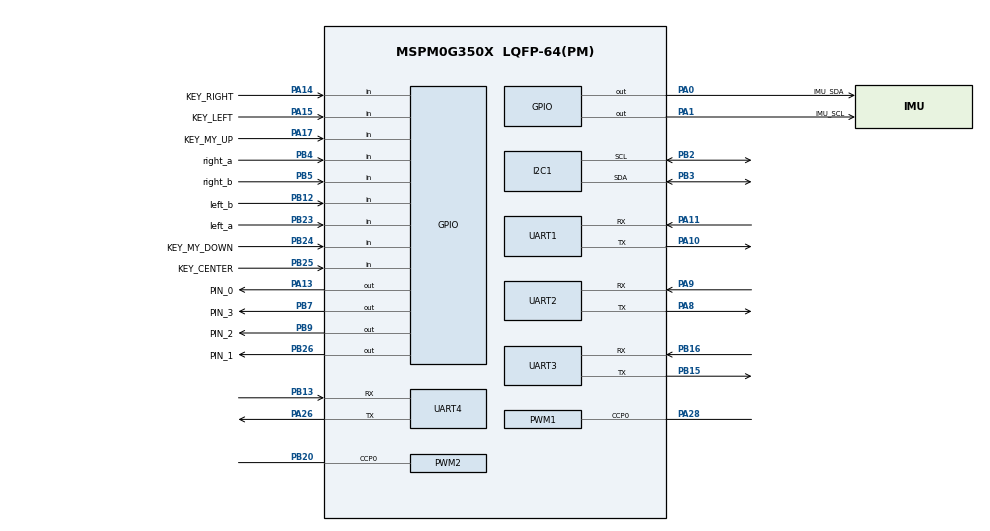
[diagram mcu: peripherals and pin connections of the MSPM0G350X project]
/**
 * @cliArgs --device "MSPM0G350X" --part "Default" --package "LQFP-64(PM)" --product "mspm0_sdk@2.09.00.00"
 * @versions {"tool":"1.27.0+4565"}
 */

/**
 * Import the modules used in this configuration.
 */
const GPIO    = scripting.addModule("/ti/driverlib/GPIO", {}, false);
const GPIO1   = GPIO.addInstance();
const GPIO2   = GPIO.addInstance();
const GPIO3   = GPIO.addInstance();
const GPIO4   = GPIO.addInstance();
const GPIO5   = GPIO.addInstance();
const GPIO7   = GPIO.addInstance();
const GPIO8   = GPIO.addInstance();
const I2C     = scripting.addModule("/ti/driverlib/I2C", {}, false);
const I2C1    = I2C.addInstance();
const PWM     = scripting.addModule("/ti/driverlib/PWM", {}, false);
const PWM1    = PWM.addInstance();
const PWM2    = PWM.addInstance();
const SYSCTL  = scripting.addModule("/ti/driverlib/SYSCTL");
const SYSTICK = scripting.addModule("/ti/driverlib/SYSTICK");
const UART    = scripting.addModule("/ti/driverlib/UART", {}, false);
const UART1   = UART.addInstance();
const UART2   = UART.addInstance();
const UART3   = UART.addInstance();
const UART4   = UART.addInstance();

/**
 * Write custom configuration values to the imported modules.
 */
const divider9       = system.clockTree["UDIV"];
divider9.divideValue = 2;

const gate7  = system.clockTree["MFCLKGATE"];
gate7.enable = true;

const gate8  = system.clockTree["MFPCLKGATE"];
gate8.enable = true;

const multiplier2         = system.clockTree["PLL_QDIV"];
multiplier2.multiplyValue = 4;

const mux4       = system.clockTree["EXHFMUX"];
mux4.inputSelect = "EXHFMUX_XTAL";

const mux8       = system.clockTree["HSCLKMUX"];
mux8.inputSelect = "HSCLKMUX_SYSPLL0";

const mux12       = system.clockTree["SYSPLLMUX"];
mux12.inputSelect = "zSYSPLLMUX_HFCLK";

const pinFunction3     = system.clockTree["HFCLKEXT"];
pinFunction3.inputFreq = 40;

const pinFunction4        = system.clockTree["HFXT"];
pinFunction4.inputFreq    = 40;
pinFunction4.enable       = true;
pinFunction4.HFXTStartup  = 100;
pinFunction4.HFCLKMonitor = true;

GPIO1.$name                         = "MOTOR_DIR_LEFT1";
GPIO1.associatedPins[0].$name       = "PIN_0";
GPIO1.associatedPins[0].pin.$assign = "PA13";

const Board = scripting.addModule("/ti/driverlib/Board", {}, false);

GPIO2.$name                         = "MOTOR_DIR_LEFT2";
GPIO2.associatedPins[0].$name       = "PIN_1";
GPIO2.associatedPins[0].pin.$assign = "PB26";

GPIO3.$name                         = "MOTOR_DIR_RIGHT1";
GPIO3.associatedPins[0].$name       = "PIN_2";
GPIO3.associatedPins[0].pin.$assign = "PB9";

GPIO4.$name                         = "MOTOR_DIR_RIGHT2";
GPIO4.associatedPins[0].$name       = "PIN_3";
GPIO4.associatedPins[0].pin.$assign = "PB7";

GPIO5.$name                              = "ENCODER";
GPIO5.associatedPins.create(4);
GPIO5.associatedPins[0].$name            = "left_a";
GPIO5.associatedPins[0].direction        = "INPUT";
GPIO5.associatedPins[0].internalResistor = "PULL_DOWN";
GPIO5.associatedPins[0].assignedPort     = "PORTB";
GPIO5.associatedPins[0].interruptEn      = true;
GPIO5.associatedPins[0].polarity         = "RISE";
GPIO5.associatedPins[0].pin.$assign      = "PB23";
GPIO5.associatedPins[1].$name            = "left_b";
GPIO5.associatedPins[1].direction        = "INPUT";
GPIO5.associatedPins[1].assignedPort     = "PORTB";
GPIO5.associatedPins[1].internalResistor = "PULL_UP";
GPIO5.associatedPins[1].interruptEn      = true;
GPIO5.associatedPins[1].polarity         = "FALL";
GPIO5.associatedPins[1].pin.$assign      = "PB12";
GPIO5.associatedPins[2].$name            = "right_a";
GPIO5.associatedPins[2].direction        = "INPUT";
GPIO5.associatedPins[2].assignedPort     = "PORTB";
GPIO5.associatedPins[2].interruptEn      = true;
GPIO5.associatedPins[2].internalResistor = "PULL_DOWN";
GPIO5.associatedPins[2].polarity         = "RISE";
GPIO5.associatedPins[2].pin.$assign      = "PB4";
GPIO5.associatedPins[3].$name            = "right_b";
GPIO5.associatedPins[3].direction        = "INPUT";
GPIO5.associatedPins[3].assignedPort     = "PORTB";
GPIO5.associatedPins[3].internalResistor = "PULL_UP";
GPIO5.associatedPins[3].interruptEn      = true;
GPIO5.associatedPins[3].polarity         = "FALL";
GPIO5.associatedPins[3].pin.$assign      = "PB5";

/* GRAY (PB10/PB11) 已移除：SERIAL_DAT/SERIAL_CLK 无代码引用，
 * 且其配套的 ADC12_0 外设已删除，属残留配置。 */

GPIO7.$name                          = "IMU";
GPIO7.associatedPins.create(2);
GPIO7.associatedPins[0].$name        = "IMU_SDA";
GPIO7.associatedPins[0].initialValue = "SET";
GPIO7.associatedPins[0].ioStructure  = "OD";
GPIO7.associatedPins[0].pin.$assign  = "PA0";
GPIO7.associatedPins[1].$name        = "IMU_SCL";
GPIO7.associatedPins[1].initialValue = "SET";
GPIO7.associatedPins[1].ioStructure  = "OD";
GPIO7.associatedPins[1].pin.$assign  = "PA1";

GPIO8.$name                              = "KEY";
GPIO8.associatedPins.create(5);
GPIO8.associatedPins[0].$name            = "KEY_MY_UP";
GPIO8.associatedPins[0].direction        = "INPUT";
GPIO8.associatedPins[0].internalResistor = "PULL_UP";
GPIO8.associatedPins[0].assignedPort     = "PORTA";
GPIO8.associatedPins[0].assignedPin      = "17";
GPIO8.associatedPins[0].pin.$assign      = "PA17";
GPIO8.associatedPins[1].$name            = "KEY_MY_DOWN";
GPIO8.associatedPins[1].direction        = "INPUT";
GPIO8.associatedPins[1].assignedPort     = "PORTB";
GPIO8.associatedPins[1].assignedPin      = "24";
GPIO8.associatedPins[1].internalResistor = "PULL_UP";
GPIO8.associatedPins[1].pin.$assign      = "PB24";
GPIO8.associatedPins[2].$name            = "KEY_LEFT";
GPIO8.associatedPins[2].direction        = "INPUT";
GPIO8.associatedPins[2].internalResistor = "PULL_UP";
GPIO8.associatedPins[2].assignedPort     = "PORTA";
GPIO8.associatedPins[2].assignedPin      = "15";
GPIO8.associatedPins[2].pin.$assign      = "PA15";
GPIO8.associatedPins[3].$name            = "KEY_RIGHT";
GPIO8.associatedPins[3].direction        = "INPUT";
GPIO8.associatedPins[3].assignedPort     = "PORTA";
GPIO8.associatedPins[3].assignedPin      = "14";
GPIO8.associatedPins[3].internalResistor = "PULL_UP";
GPIO8.associatedPins[3].pin.$assign      = "PA14";
GPIO8.associatedPins[4].$name            = "KEY_CENTER";
GPIO8.associatedPins[4].direction        = "INPUT";
GPIO8.associatedPins[4].internalResistor = "PULL_UP";
GPIO8.associatedPins[4].assignedPort     = "PORTB";
GPIO8.associatedPins[4].assignedPin      = "25";
GPIO8.associatedPins[4].pin.$assign      = "PB25";

I2C1.$name                           = "I2C_0";
I2C1.basicEnableController           = true;
I2C1.basicControllerStandardBusSpeed = "Fast";
I2C1.peripheral.$assign              = "I2C1";
I2C1.peripheral.sdaPin.$assign       = "PB3";
I2C1.peripheral.sclPin.$assign       = "PB2";
I2C1.sdaPinConfig.$name              = "ti_driverlib_gpio_GPIOPinGeneric6";
I2C1.sclPinConfig.$name              = "ti_driverlib_gpio_GPIOPinGeneric7";

PWM1.$name                              = "MOTOR_PWM_LEFT";
PWM1.clockPrescale                      = 2;
PWM1.timerStartTimer                    = true;
PWM1.pwmMode                            = "EDGE_ALIGN_UP";
PWM1.ccIndex                            = [0];
PWM1.clockDivider                       = 2;
PWM1.PWM_CHANNEL_0.$name                = "ti_driverlib_pwm_PWMTimerCC0";
PWM1.ccp0PinConfig.direction            = scripting.forceWrite("OUTPUT");
PWM1.ccp0PinConfig.hideOutputInversion  = scripting.forceWrite(false);
PWM1.ccp0PinConfig.onlyInternalResistor = scripting.forceWrite(false);
PWM1.ccp0PinConfig.passedPeripheralType = scripting.forceWrite("Digital");
PWM1.ccp0PinConfig.$name                = "ti_driverlib_gpio_GPIOPinGeneric4";
PWM1.peripheral.$assign                 = "TIMG7";
PWM1.peripheral.ccp0Pin.$assign         = "PA28";

PWM2.$name                              = "MOTOR_PWM_RIGHT";
PWM2.ccIndex                            = [0];
PWM2.pwmMode                            = "EDGE_ALIGN_UP";
PWM2.timerStartTimer                    = true;
PWM2.clockDivider                       = 4;
PWM2.PWM_CHANNEL_0.$name                = "ti_driverlib_pwm_PWMTimerCC1";
PWM2.ccp0PinConfig.$name                = "ti_driverlib_gpio_GPIOPinGeneric5";
PWM2.ccp0PinConfig.direction            = scripting.forceWrite("OUTPUT");
PWM2.ccp0PinConfig.hideOutputInversion  = scripting.forceWrite(false);
PWM2.ccp0PinConfig.onlyInternalResistor = scripting.forceWrite(false);
PWM2.ccp0PinConfig.passedPeripheralType = scripting.forceWrite("Digital");
PWM2.peripheral.$assign                 = "TIMG12";
PWM2.peripheral.ccp0Pin.$assign         = "PB20";

SYSCTL.forceDefaultClkConfig = true;
SYSCTL.clockTreeEn           = true;
SYSCTL.validateClkStatus     = true;

SYSTICK.periodEnable      = true;
SYSTICK.interruptEnable   = true;
SYSTICK.systickEnable     = true;
SYSTICK.period            = 80000;
SYSTICK.interruptPriority = "0";

UART1.$name                    = "UART_0";
UART1.uartClkSrc               = "MFCLK";
UART1.targetBaudRate           = 115200;
UART1.enabledInterrupts        = ["RX"];
UART1.peripheral.$assign       = "UART0";
UART1.peripheral.rxPin.$assign = "PA11";
UART1.peripheral.txPin.$assign = "PA10";
UART1.txPinConfig.$name        = "ti_driverlib_gpio_GPIOPinGeneric0";
UART1.rxPinConfig.$name        = "ti_driverlib_gpio_GPIOPinGeneric1";

UART2.$name                                = "UART_1";
UART2.targetBaudRate                       = 115200;
UART2.enableFIFO                           = true;
UART2.rxFifoThreshold                      = "DL_UART_RX_FIFO_LEVEL_ONE_ENTRY";
UART2.rxTimeoutValue                       = 10;
UART2.enabledDMARXTriggers                 = "DL_UART_DMA_INTERRUPT_RX";
UART2.enabledInterrupts                    = ["RX_TIMEOUT_ERROR"];
UART2.interruptPriority                    = "1";
UART2.peripheral.$assign                   = "UART1";
UART2.peripheral.rxPin.$assign             = "PA9";
UART2.peripheral.txPin.$assign             = "PA8";
UART2.txPinConfig.$name                    = "ti_driverlib_gpio_GPIOPinGeneric2";
UART2.txPinConfig.enableConfig             = true;
UART2.rxPinConfig.$name                    = "ti_driverlib_gpio_GPIOPinGeneric3";
UART2.DMA_CHANNEL_RX.$name                 = "DMA_CH0";
UART2.DMA_CHANNEL_RX.srcLength             = "BYTE";
UART2.DMA_CHANNEL_RX.dstLength             = "BYTE";
UART2.DMA_CHANNEL_RX.configureTransferSize = true;
UART2.DMA_CHANNEL_RX.transferMode          = "FULL_CH_REPEAT_SINGLE";
UART2.DMA_CHANNEL_RX.transferSize          = 256;
UART2.DMA_CHANNEL_RX.addressMode           = "f2b";
UART2.DMA_CHANNEL_RX.peripheral.$assign    = "DMA_CH0";

UART3.$name                                = "UART_2";
UART3.targetBaudRate                       = 115200;
UART3.enableFIFO                           = true;
UART3.rxFifoThreshold                      = "DL_UART_RX_FIFO_LEVEL_ONE_ENTRY";
UART3.rxTimeoutValue                       = 10;
UART3.enabledDMARXTriggers                 = "DL_UART_DMA_INTERRUPT_RX";
UART3.enabledInterrupts                    = ["RX_TIMEOUT_ERROR"];
UART3.interruptPriority                    = "1";
UART3.peripheral.$assign                   = "UART2";
UART3.peripheral.rxPin.$assign             = "PB16";
UART3.peripheral.txPin.$assign             = "PB15";
UART3.txPinConfig.$name                    = "ti_driverlib_gpio_GPIOPinGeneric9";
UART3.txPinConfig.enableConfig             = true;
UART3.rxPinConfig.$name                    = "ti_driverlib_gpio_GPIOPinGeneric10";
UART3.DMA_CHANNEL_RX.$name                 = "DMA_CH1";
UART3.DMA_CHANNEL_RX.srcLength             = "BYTE";
UART3.DMA_CHANNEL_RX.dstLength             = "BYTE";
UART3.DMA_CHANNEL_RX.configureTransferSize = true;
UART3.DMA_CHANNEL_RX.transferMode          = "FULL_CH_REPEAT_SINGLE";
UART3.DMA_CHANNEL_RX.transferSize          = 256;
UART3.DMA_CHANNEL_RX.addressMode           = "f2b";
UART3.DMA_CHANNEL_RX.peripheral.$assign    = "DMA_CH1";

UART4.$name                                = "UART_3";
UART4.targetBaudRate                       = 115200;
UART4.enableFIFO                           = true;
UART4.rxFifoThreshold                      = "DL_UART_RX_FIFO_LEVEL_ONE_ENTRY";
UART4.rxTimeoutValue                       = 10;
UART4.enabledDMARXTriggers                 = "DL_UART_DMA_INTERRUPT_RX";
UART4.enabledInterrupts                    = ["RX_TIMEOUT_ERROR"];
UART4.interruptPriority                    = "1";
UART4.uartClkDiv                           = "2";
UART4.peripheral.$assign                   = "UART3";
UART4.peripheral.rxPin.$assign             = "PB13";
UART4.peripheral.txPin.$assign             = "PA26";
UART4.txPinConfig.$name                    = "ti_driverlib_gpio_GPIOPinGeneric11";
UART4.txPinConfig.enableConfig             = true;
UART4.rxPinConfig.$name                    = "ti_driverlib_gpio_GPIOPinGeneric12";
UART4.DMA_CHANNEL_RX.$name                 = "DMA_CH2";
UART4.DMA_CHANNEL_RX.srcLength             = "BYTE";
UART4.DMA_CHANNEL_RX.dstLength             = "BYTE";
UART4.DMA_CHANNEL_RX.configureTransferSize = true;
UART4.DMA_CHANNEL_RX.transferMode          = "FULL_CH_REPEAT_SINGLE";
UART4.DMA_CHANNEL_RX.transferSize          = 256;
UART4.DMA_CHANNEL_RX.addressMode           = "f2b";
UART4.DMA_CHANNEL_RX.peripheral.$assign    = "DMA_CH2";

/**
 * Pinmux solution for unlocked pins/peripherals. This ensures that minor changes to the automatic solver in a future
 * version of the tool will not impact the pinmux you originally saw.  These lines can be completely deleted in order to
 * re-solve from scratch.
 */
pinFunction4.peripheral.$suggestSolution           = "SYSCTL";
pinFunction4.peripheral.hfxInPin.$suggestSolution  = "PA5";
pinFunction4.peripheral.hfxOutPin.$suggestSolution = "PA6";
Board.peripheral.$suggestSolution                  = "DEBUGSS";
Board.peripheral.swclkPin.$suggestSolution         = "PA20";
Board.peripheral.swdioPin.$suggestSolution         = "PA19";
